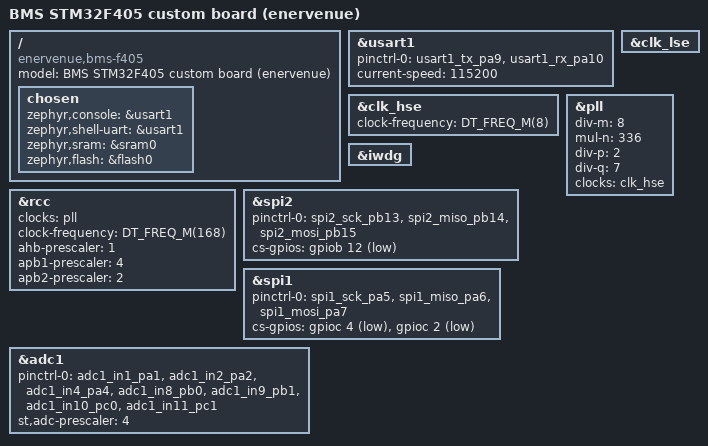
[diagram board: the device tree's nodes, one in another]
/*
 * BMS STM32F405 自定义板（enervenue / S16100B 目标）devicetree。
 *
 * 引脚权威（用户 2026-07-02 定案）：`docs/reference/hardware/software-interface.md` §9
 * （原理图 V0.4 校对版）+ 原理图 PDF 为准；`STM32F405RGT6_BMS.ioc`（CubeMX 草稿）弃用。
 *
 * 本增量：时钟地基 + console(USART1 PA9/10, §9 主 RS485 口)。其余外设（SPI2/AFE、
 * SPI1/flash、ADC1、IWDG、RTC）随各自 Phase 2-⑥/Phase 3 backend 逐个补（引脚照 §9）。
 * 注：USART1 物理上是隔离 RS485 主口（经 CA-IS2092A，方向脚 PA11=DE/RE）；此处作
 * 开发期 Zephyr console（RS485 收发方向控制与 Modbus 9600 属 Phase 3 comm 驱动，届时
 * 与 console 复用一并厘清）。
 *
 * 地基频率（.ioc 与 §9 一致，已确认）：HSE 8MHz、LSE 32.768k、SYSCLK 168MHz。
 */
/dts-v1/;

#include <st/f4/stm32f405Xg.dtsi>
#include <st/f4/stm32f405rgtx-pinctrl.dtsi>
#include <zephyr/dt-bindings/gpio/gpio.h>

/ {
	model = "BMS STM32F405 custom board (enervenue)";
	compatible = "enervenue,bms-f405";

	chosen {
		zephyr,console = &usart1;
		zephyr,shell-uart = &usart1;
		zephyr,sram = &sram0;
		zephyr,flash = &flash0;
	};
};

/* 主 RS485 口 USART1（PA9 TX / PA10 RX，§9）——开发期作 Zephyr console。 */
&usart1 {
	pinctrl-0 = <&usart1_tx_pa9 &usart1_rx_pa10>;
	pinctrl-names = "default";
	current-speed = <115200>;
	status = "okay";
};

/*
 * 时钟树：HSE 8MHz → PLL → SYSCLK 168MHz（F4 标准：VCO=8/8*336=336MHz，/P=2→168MHz，
 * /Q=7→48MHz 供 USB）。HSE/LSE 频率与 .ioc、原理图一致；bus 分频 AHB÷1/APB1÷4/APB2÷2。
 */
&clk_hse {
	clock-frequency = <DT_FREQ_M(8)>;
	status = "okay";
};

&clk_lse {
	status = "okay";
};

&pll {
	div-m = <8>;
	mul-n = <336>;
	div-p = <2>;
	div-q = <7>;
	clocks = <&clk_hse>;
	status = "okay";
};

&rcc {
	clocks = <&pll>;
	clock-frequency = <DT_FREQ_M(168)>;
	ahb-prescaler = <1>;
	apb1-prescaler = <4>;
	apb2-prescaler = <2>;
};

/* 内部独立看门狗（IWDG，无外部脚）——hal/wdt STM32 后端的设备（软先于硬兜底，§7）。 */
&iwdg {
	status = "okay";
};

/*
 * ---------------------------------------------------------------------------
 * 板级外设节点（引脚按 software-interface.md §9；**编译级硬件描述**为 Phase 3 铺路）。
 * 各总线/ADC/RTC 的**从设备与 backend**（SH3673520、W25Q32、SD、ADC 采集、RTC 时间戳）
 * 属 Phase 3（真板/HIL），此处只声明控制器节点 + pinctrl/CS，使驱动实例化、编译门守护。
 * ---------------------------------------------------------------------------
 */

/* SPI2 → AFE(SH3673520)：SCK PB13 / MISO PB14 / MOSI PB15；CS PB12（GPIO 手动，低有效）。 */
&spi2 {
	pinctrl-0 = <&spi2_sck_pb13 &spi2_miso_pb14 &spi2_mosi_pb15>;
	pinctrl-names = "default";
	cs-gpios = <&gpiob 12 GPIO_ACTIVE_LOW>;
	status = "okay";
};

/* SPI1 → 外部 Flash(W25Q32) + SD 卡（共享总线）：SCK PA5 / MISO PA6 / MOSI PA7；
 * 片选 FLASH_CS PC4、SD_CS PC2（分时选通）。从设备节点属 Phase 3。 */
&spi1 {
	pinctrl-0 = <&spi1_sck_pa5 &spi1_miso_pa6 &spi1_mosi_pa7>;
	pinctrl-names = "default";
	cs-gpios = <&gpioc 4 GPIO_ACTIVE_LOW>, <&gpioc 2 GPIO_ACTIVE_LOW>;
	status = "okay";
};

/* ADC1：温度/电压/进水采集通道（PA1/2/4、PB0/1、PC0/1，§9）。通道 io-channels 配置随
 * Phase 3 采集 backend/overlay。注：§9 与 §4.4 对 PA1/PB1 归属有笔误待硬件核（§9 末）。 */
&adc1 {
	pinctrl-0 = <&adc1_in1_pa1 &adc1_in2_pa2 &adc1_in4_pa4
		     &adc1_in8_pb0 &adc1_in9_pb1 &adc1_in10_pc0 &adc1_in11_pc1>;
	pinctrl-names = "default";
	st,adc-prescaler = <4>; /* APB2 84MHz ÷4 = 21MHz < 36MHz ADC 上限 */
	status = "okay";
};

/*
 * RTC（LSE 32.768k，§9）延后到 Phase 3：STM32 RTC 需 dts 显式选时钟源
 * （STM32_SRC_LSE RTC_SEL + BDCR 门控），与真实时间源 backend 一并配置/核实，不在编译级铺。
 */
